AUTOSAR XML (schema 4-0-3)
package /ComponentTypes
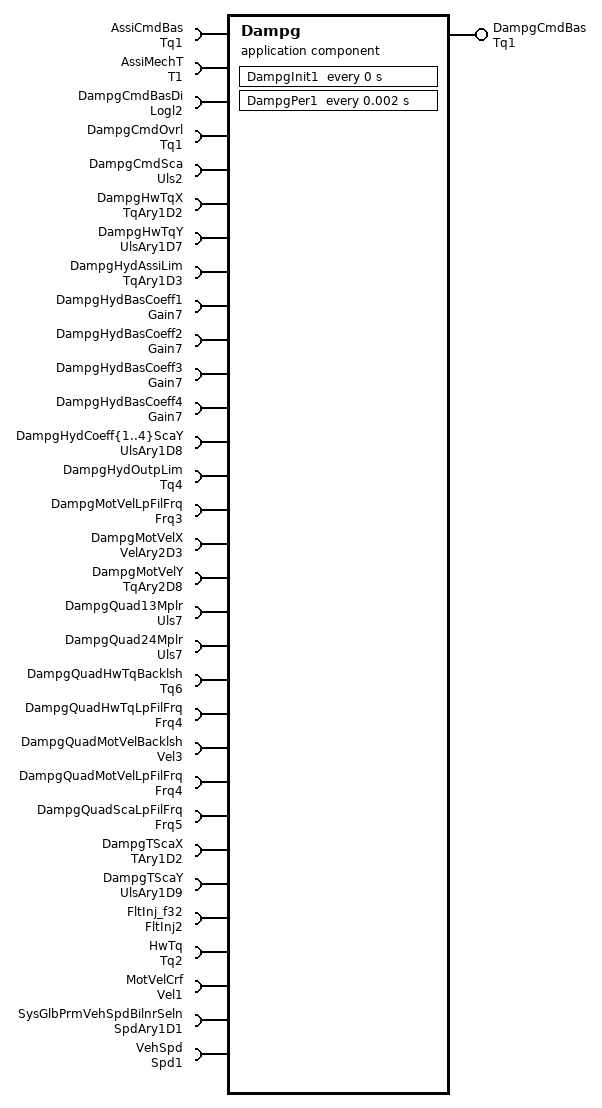
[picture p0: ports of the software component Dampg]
  application sw component type Dampg
    provide port DampgCmdBas: nonqueued-sender-com-spec{data-element=Val, init-value=0}, provided-interface=Tq1
    34 x require port:
      AssiCmdBas: nonqueued-receiver-com-spec{data-element=Val, filter=data-filter-type=ALWAYS, init-value=0}, required-interface=Tq1
      AssiMechT: nonqueued-receiver-com-spec{data-element=Val, filter=data-filter-type=ALWAYS, init-value=0}, required-interface=T1
      DampgCmdBasDi: nonqueued-receiver-com-spec{data-element=Logl, filter=data-filter-type=ALWAYS, init-value=0}, required-interface=Logl2
      DampgCmdOvrl: nonqueued-receiver-com-spec{data-element=Val, filter=data-filter-type=ALWAYS, init-value=0}, required-interface=Tq1
      DampgCmdSca: nonqueued-receiver-com-spec{data-element=Val, filter=data-filter-type=ALWAYS, init-value=0}, required-interface=Uls2
      DampgHwTqX: parameter-require-com-spec{init-value=[8, 10], parameter=Ary1D}, required-interface=TqAry1D2
      DampgHwTqY: parameter-require-com-spec{init-value=[1, 0], parameter=Ary1D}, required-interface=UlsAry1D7
      DampgHydAssiLim: parameter-require-com-spec{init-value=12 x 8.8, parameter=Ary1D}, required-interface=TqAry1D3
      DampgHydBasCoeff1: parameter-require-com-spec{init-value=0.0005, parameter=Val}, required-interface=Gain7
      DampgHydBasCoeff2: parameter-require-com-spec{init-value=2e-05, parameter=Val}, required-interface=Gain7
      DampgHydBasCoeff3: parameter-require-com-spec{init-value=0.006, parameter=Val}, required-interface=Gain7
      DampgHydBasCoeff4: parameter-require-com-spec{init-value=9e-06, parameter=Val}, required-interface=Gain7
      DampgHydCoeff{1..4}ScaY: parameter-require-com-spec{init-value=12 x 1, parameter=Ary1D}, required-interface=UlsAry1D8
      DampgHydOutpLim: parameter-require-com-spec{init-value=0, parameter=Val}, required-interface=Tq4
      DampgMotVelLpFilFrq: parameter-require-com-spec{init-value=15, parameter=Val}, required-interface=Frq3
      DampgMotVelX: parameter-require-com-spec{init-value=12 x [2.063, 10.188, 21.375, 34.625, 54.5, 78.75, 103.938, 127, 150.063, 173.188, 219.313, 277.063, 369.375], parameter=Ary2D}, required-interface=VelAry2D3
      DampgMotVelY: parameter-require-com-spec{init-value=[13 x 0, 13 x 0, 13 x 0, 13 x 0, [0, 0, 0.0005, 0.0015, 0.0034, 0.0068, 0.0117, 0.0176, 0.0244, 0.0327, 0.0522, 0.0835, 0.1484], [0.0005, 0.0024, 0.0063, 0.0122, 0.0234, 0.0415, 0.0645, 0.0898, 0.1196, 0.1528, 0.2324, 0.354, 0.6021], [0.0024, 0.0122, 0.0264, 0.0454, 0.0776, 0.1226, 0.1758, 0.2305, 0.2915, 0.3579, 0.5083, 0.729, 1.1572], [0.0049, 0.0239, 0.0518, 0.0879, 0.147, 0.228, 0.3218, 0.4175, 0.5215, 0.6343, 0.8857, 1.2495, 1.9438], [0.0049, 0.0239, 0.0518, 0.0879, 0.147, 0.228, 0.3218, 0.4175, 0.5215, 0.6343, 0.8857, 1.2495, 1.9438], [0.0049, 0.0239, 0.0518, 0.0879, 0.147, 0.228, 0.3218, 0.4175, 0.5215, 0.6343, 0.8857, 1.2495, 1.9438], [0.0049, 0.0239, 0.0518, 0.0879, 0.147, 0.228, 0.3218, 0.4175, 0.5215, 0.6343, 0.8857, 1.2495, 1.9438], [0.0049, 0.0239, 0.0518, 0.0879, 0.147, 0.228, 0.3218, 0.4175, 0.5215, 0.6343, 0.8857, 1.2495, 1.9438]], parameter=Ary2D}, required-interface=TqAry2D8
      DampgQuad13Mplr: parameter-require-com-spec{init-value=1, parameter=Val}, required-interface=Uls7
      DampgQuad24Mplr: parameter-require-com-spec{init-value=1, parameter=Val}, required-interface=Uls7
      DampgQuadHwTqBacklsh: parameter-require-com-spec{init-value=0, parameter=Val}, required-interface=Tq6
      DampgQuadHwTqLpFilFrq: parameter-require-com-spec{init-value=15, parameter=Val}, required-interface=Frq4
      DampgQuadMotVelBacklsh: parameter-require-com-spec{init-value=0, parameter=Val}, required-interface=Vel3
      DampgQuadMotVelLpFilFrq: parameter-require-com-spec{init-value=15, parameter=Val}, required-interface=Frq4
      DampgQuadScaLpFilFrq: parameter-require-com-spec{init-value=15, parameter=Val}, required-interface=Frq5
      DampgTScaX: parameter-require-com-spec{init-value=[-40, -35, -30, -20, -10, 0, 10, 20, 30, 40, 50, 60, 70, 90], parameter=Ary1D}, required-interface=TAry1D2
      DampgTScaY: parameter-require-com-spec{init-value=14 x 1, parameter=Ary1D}, required-interface=UlsAry1D9
      FltInj_f32: required-interface=FltInj2
      HwTq: nonqueued-receiver-com-spec{data-element=Val, filter=data-filter-type=ALWAYS, init-value=0}, required-interface=Tq2
      MotVelCrf: nonqueued-receiver-com-spec{data-element=Val, filter=data-filter-type=ALWAYS, init-value=0}, required-interface=Vel1
      SysGlbPrmVehSpdBilnrSeln: parameter-require-com-spec{init-value=[0, 5, 15, 30, 60, 80, 100, 120, 150, 180, 200, 220], parameter=Ary1D}, required-interface=SpdAry1D1
      VehSpd: nonqueued-receiver-com-spec{data-element=Val, filter=data-filter-type=ALWAYS, init-value=0}, required-interface=Spd1
    behavior Dampg_InternalBehavior: data-type-mapping=Nexteer
      ar-typed-per-instance-memorys:
        16 x data, all with sw-calibration-access=READ-ONLY:
          dDampgAssiMechTSca: type=T8
          dDampgCoeff{1..4}Term: type=Uls22
          dDampgHwTqSca: type=Uls2
          dDampgMotVelDampgCmd: type=Tq1
          dDampgQuadHwTqBacklsh: type=Tq18
          dDampgQuadMotVelBacklsh: type=Vel8
          MotVelDampgLpFil: type=FilLpRec1
          PrevHwTqBacklshOutp: type=Tq18
          PrevHydOutpLim: type=Tq1
          PrevMotVelBacklshOutp: type=Vel8
          QuadDampgHwTqLpFil: type=FilLpRec1
          QuadDampgMotVelLpFil: type=FilLpRec1
          QuadDampgScaLpFil: type=FilLpRec1
      timing event Dampg_InitEvent: start-on-event=DampgInit1, period=0
      timing event TMT_DampgPer1: start-on-event=DampgPer1, period=0.002
      runnable DampgInit1
      runnable DampgPer1
        data-receive-point-by-arguments:
          8 x access:
            REC_AssiCmdBas_Val: accessed-variable=AssiCmdBas.Val
            REC_AssiMechT_Val: accessed-variable=AssiMechT.Val
            REC_DampgCmdBasDi_Logl: accessed-variable=DampgCmdBasDi.Logl
            REC_DampgCmdOvrl_Val: accessed-variable=DampgCmdOvrl.Val
            REC_DampgCmdSca_Val: accessed-variable=DampgCmdSca.Val
            REC_HwTq_Val: accessed-variable=HwTq.Val
            REC_MotVelCrf_Val: accessed-variable=MotVelCrf.Val
            REC_VehSpd_Val: accessed-variable=VehSpd.Val
        data-send-points:
          access SEND_DampgCmdBas_Val: accessed-variable=DampgCmdBas.Val
        sync call SC_FltInj_f32_Oper: operation=FltInj_f32.Oper, timeout=0
  swc implementation Dampg_Implementation: behavior=Dampg_InternalBehavior
    code-descriptors:
      code Default: artifact-descriptors=autosar-engineering-object={short-label=Default, category=SWSRC}
